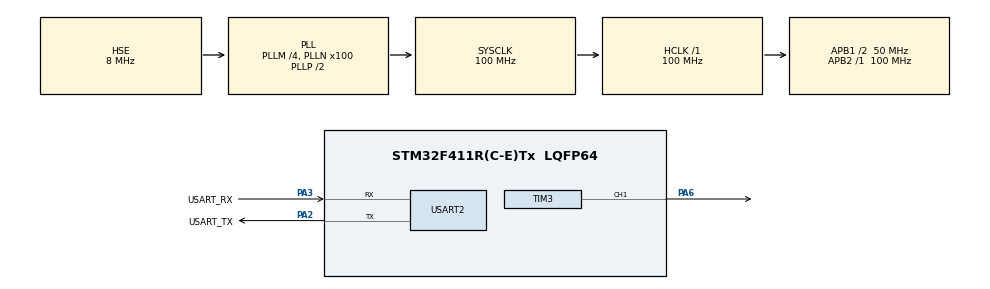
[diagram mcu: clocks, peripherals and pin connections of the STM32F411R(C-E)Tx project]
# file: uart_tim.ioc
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Mcu.Family=STM32F4
Mcu.Name=STM32F411R(C-E)Tx
Mcu.Package=LQFP64
NVIC.PriorityGroup=NVIC_PRIORITYGROUP_4
NVIC.TIM3_IRQn=true\:0\:0\:false\:false\:true\:true\:true\:true
NVIC.USART2_IRQn=true\:0\:0\:false\:false\:true\:true\:true\:true
PA13.GPIO_Label=TMS
PA13.Mode=Serial_Wire
PA13.Signal=SYS_JTMS-SWDIO
PA14.GPIO_Label=TCK
PA14.Mode=Serial_Wire
PA14.Signal=SYS_JTCK-SWCLK
PA2.GPIO_Label=USART_TX
PA2.Mode=Asynchronous
PA2.Signal=USART2_TX
PA3.GPIO_Label=USART_RX
PA3.Mode=Asynchronous
PA3.Signal=USART2_RX
PA6.Signal=S_TIM3_CH1
PH0\ -\ OSC_IN.Mode=HSE-External-Oscillator
PH0\ -\ OSC_IN.Signal=RCC_OSC_IN
PH1\ -\ OSC_OUT.Mode=HSE-External-Oscillator
PH1\ -\ OSC_OUT.Signal=RCC_OSC_OUT
ProjectManager.HeapSize=0x200
ProjectManager.StackSize=0x400
ProjectManager.TargetToolchain=STM32CubeIDE
RCC.48MHZClocksFreq_Value=50000000
RCC.AHBFreq_Value=100000000
RCC.APB1CLKDivider=RCC_HCLK_DIV2
RCC.APB1Freq_Value=50000000
RCC.APB1TimFreq_Value=100000000
RCC.APB2Freq_Value=100000000
RCC.APB2TimFreq_Value=100000000
RCC.CortexFreq_Value=100000000
RCC.FLatency-AdvancedSettings=FLASH_LATENCY_3
RCC.HCLKFreq_Value=100000000
RCC.HSE_VALUE=8000000
RCC.HSI_VALUE=16000000
RCC.LSE_VALUE=32768
RCC.PLLM=4
RCC.PLLN=100
RCC.PLLSourceVirtual=RCC_PLLSOURCE_HSE
RCC.SYSCLKFreq_VALUE=100000000
RCC.SYSCLKSource=RCC_SYSCLKSOURCE_PLLCLK
RCC.VCOOutputFreq_Value=200000000
SH.S_TIM3_CH1.0=TIM3_CH1,PWM Generation1 CH1
TIM3.Channel-PWM\ Generation1\ CH1=TIM_CHANNEL_1
TIM3.Period=2000-1
TIM3.Prescaler=1000-1
USART2.VirtualMode=VM_ASYNC
VP_TIM3_VS_ClockSourceINT.Mode=Internal
board=NUCLEO-F411RE

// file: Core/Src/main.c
/* USER CODE BEGIN Header */
/**
 ******************************************************************************
 * @file           : main.c
 * @brief          : Main program body
 ******************************************************************************
 * @attention
 *
 * Copyright (c) 2025 STMicroelectronics.
 * All rights reserved.
 *
 * This software is licensed under terms that can be found in the LICENSE file
 * in the root directory of this software component.
 * If no LICENSE file comes with this software, it is provided AS-IS.
 *
 ******************************************************************************
 */
/* USER CODE END Header */
#include "main.h"
#include "tim.h"
#include "usart.h"
#include "gpio.h"

/* USER CODE BEGIN Includes */
#include "main.h"
#include "tim.h"
#include "usart.h"
#include "gpio.h"
#include "string.h"
/* USER CODE END Includes */

/* USER CODE BEGIN PV */
uint8_t rxData;
/* USER CODE END PV */

void SystemClock_Config(void);
/* USER CODE BEGIN PFP */
void HAL_UART_RxCpltCallback(UART_HandleTypeDef *huart)
{

  //USART2이면
  if(huart->Instance==USART2)
  {
    //호출해서 활성화 시킴
    //receive는 폴링 방식 안쓴다
    HAL_UART_Receive_IT(&huart2, &rxData, sizeof(rxData));

    //펄스 폭 저장할 변수(0.5ms 기준)
    uint32_t pulse_width = 0;

    switch (rxData)
    {
      case 'a': // -90도 (1ms)
        pulse_width = 500; // μs
        HAL_UART_Transmit(&huart2, (uint8_t*)"is -90\r\n", strlen("is -90\r\n"), 0xFFFF);
        break;

      case 'b': // 0도 (1.5ms)
        pulse_width = 1500; // μs
        HAL_UART_Transmit(&huart2, (uint8_t*)"is 0\r\n", strlen("is 0\r\n"), 0xFFFF);
        break;

      case 'c': // +90도 (2ms)
        pulse_width = 2500; // μs
        HAL_UART_Transmit(&huart2, (uint8_t*)"is 90\r\n", strlen("is 90\r\n"), 0xFFFF);
        break;

      default:
        HAL_UART_Transmit(&huart2, (uint8_t*)"error\r\n", strlen("error\r\n"), 0xFFFF);
        return;
    }

    // PWM 펄스 폭 계산 (20ms 주기 기준)
    //htim3.Init.Period: 타이머 한주기 값 호출 변수 (20000-1 = 19999)
    //timer에 AutoReload Registe값
    TIM3->CCR1 = (pulse_width * (htim3.Init.Period + 1)) / 20000;

  }

}

/* USER CODE END PFP */

int main(void)
{

  /* MCU Configuration--------------------------------------------------------*/

  /* Reset of all peripherals, Initializes the Flash interface and the Systick. */
  HAL_Init();

  /* Configure the system clock */
  SystemClock_Config();

  /* Initialize all configured peripherals */
  MX_GPIO_Init();
  MX_USART2_UART_Init();
  MX_TIM3_Init();
  /* USER CODE BEGIN 2 */

  //받는 인터럽트 활성화
  HAL_UART_Receive_IT(&huart2, &rxData, sizeof(rxData));

  //pwm 활성화
  HAL_TIM_PWM_Start(&htim3, TIM_CHANNEL_1);

  //서보모터 중앙 맞춤
  TIM3->CCR1 = (1500 * (htim3.Init.Period + 1)) / 20000;

  /* USER CODE END 2 */

  /* Infinite loop */
  while (1)
  {

  }
}

void SystemClock_Config(void)
{
  RCC_OscInitTypeDef RCC_OscInitStruct = {0};
  RCC_ClkInitTypeDef RCC_ClkInitStruct = {0};

  /** Configure the main internal regulator output voltage
  */
  __HAL_RCC_PWR_CLK_ENABLE();
  __HAL_PWR_VOLTAGESCALING_CONFIG(PWR_REGULATOR_VOLTAGE_SCALE1);

  /** Initializes the RCC Oscillators according to the specified parameters
  * in the RCC_OscInitTypeDef structure.
  */
  RCC_OscInitStruct.OscillatorType = RCC_OSCILLATORTYPE_HSE;
  RCC_OscInitStruct.HSEState = RCC_HSE_ON;
  RCC_OscInitStruct.PLL.PLLState = RCC_PLL_ON;
  RCC_OscInitStruct.PLL.PLLSource = RCC_PLLSOURCE_HSE;
  RCC_OscInitStruct.PLL.PLLM = 4;
  RCC_OscInitStruct.PLL.PLLN = 100;
  RCC_OscInitStruct.PLL.PLLP = RCC_PLLP_DIV2;
  RCC_OscInitStruct.PLL.PLLQ = 4;
  if (HAL_RCC_OscConfig(&RCC_OscInitStruct) != HAL_OK)
  {
    Error_Handler();
  }

  /** Initializes the CPU, AHB and APB buses clocks
  */
  RCC_ClkInitStruct.ClockType = RCC_CLOCKTYPE_HCLK|RCC_CLOCKTYPE_SYSCLK
                              |RCC_CLOCKTYPE_PCLK1|RCC_CLOCKTYPE_PCLK2;
  RCC_ClkInitStruct.SYSCLKSource = RCC_SYSCLKSOURCE_PLLCLK;
  RCC_ClkInitStruct.AHBCLKDivider = RCC_SYSCLK_DIV1;
  RCC_ClkInitStruct.APB1CLKDivider = RCC_HCLK_DIV2;
  RCC_ClkInitStruct.APB2CLKDivider = RCC_HCLK_DIV1;

  if (HAL_RCC_ClockConfig(&RCC_ClkInitStruct, FLASH_LATENCY_3) != HAL_OK)
  {
    Error_Handler();
  }
}

void Error_Handler(void)
{
  __disable_irq();
  while (1)
  {
  }
}
